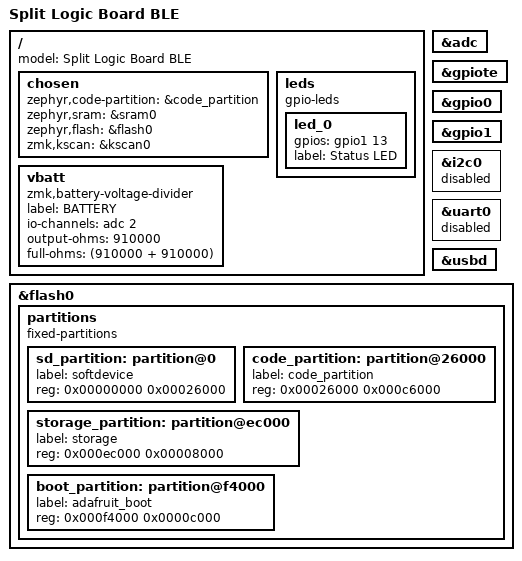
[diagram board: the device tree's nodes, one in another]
/*
 * Copyright (c) 2021 Kazuyuki Arimatsu
 *
 * SPDX-License-Identifier: MIT
 */

/dts-v1/;
#include <nordic/nrf52840_qiaa.dtsi>
#include "connector.dtsi"
#include "kscan.dtsi"

/ {
	model = "Split Logic Board BLE";

	chosen {
		zephyr,code-partition = &code_partition;
		zephyr,sram = &sram0;
		zephyr,flash = &flash0;
		zmk,kscan = &kscan0;
	};

	leds {
		compatible = "gpio-leds";
		led_0 {
			gpios = <&gpio1 13 GPIO_ACTIVE_HIGH>;
			label = "Status LED";
		};
	};

	vbatt {
		compatible = "zmk,battery-voltage-divider";
		label = "BATTERY";
		io-channels = <&adc 2>; //P0.04
		output-ohms = <910000>;
		full-ohms = <(910000 + 910000)>;
	};

	//TODO SPI for serial LEDs
};

&adc {
	status = "okay";
};

&gpiote {
	status = "okay";
};

&gpio0 {
	status = "okay";
};

&gpio1 {
	status = "okay";
};

&i2c0 {
	status = "disabled";
};

&uart0 {
	status = "disabled";
};

&usbd {
	status = "okay";
};

&flash0 {
	/*
	 * For more information, see:
	 * http://docs.zephyrproject.org/latest/devices/dts/flash_partitions.html
	 */
	partitions {
		compatible = "fixed-partitions";
		#address-cells = <1>;
		#size-cells = <1>;

		sd_partition: partition@0 {
			label = "softdevice";
			reg = <0x00000000 0x00026000>;
		};
		code_partition: partition@26000 {
			label = "code_partition";
			reg = <0x00026000 0x000c6000>;
		};

		/*
		 * The flash starting at 0x000ec000 and ending at
		 * 0x000f3fff is reserved for use by the application.
		 */

		/*
		 * Storage partition will be used by FCB/LittleFS/NVS
		 * if enabled.
		 */
		storage_partition: partition@ec000 {
			label = "storage";
			reg = <0x000ec000 0x00008000>;
		};

		boot_partition: partition@f4000 {
			label = "adafruit_boot";
			reg = <0x000f4000 0x0000c000>;
		};
	};
};
